# R7FA8D1BH register map
Vendor: Renesas; Series: RA8; File version: 1.2
CPU: CM85 r0p0, little endian, MPU, FPU, VTOR, 4 interrupt priority bits
Registers are 32-bit, read-write, reset 0x0 unless marked. A register's access mark holds for its fields unless they carry their own. Offsets are from the block's base; [hi:lo] are bit positions.

## ETHERC0 — Ethernet Controller Channel 0
Base 0x40354100
Same registers: ETHERC0_NS 0x50354100
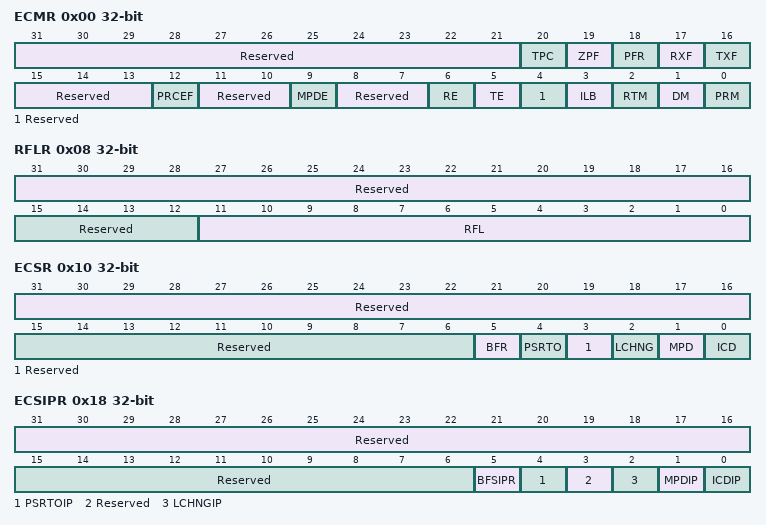
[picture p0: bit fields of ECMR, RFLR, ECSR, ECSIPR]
0x00 ECMR — ETHERC Mode Register
  [31:21] Reserved — These bits are read as 00000000000. The write value should be 00000000000.
  [20] TPC — PAUSE Frame Transmit
    0=PAUSE frame is transmitted even during a PAUSE period; 1=PAUSE frame is not transmitted during a PAUSE period
  [19] ZPF — 0 Time PAUSE Frame Enable
    0=PAUSE frame that contains the pause_time parameter of 0 is not used; 1=PAUSE frame that contains the pause_time parameter of 0 is used
  [18] PFR — PAUSE Frame Receive Mode
    0=PAUSE frame is not transferred to the EDMAC; 1=PAUSE frame is transferred to the EDMAC
  [17] RXF — Receive Flow Control Operating Mode
    0=PAUSE frame detection is disabled; 1=PAUSE frame detection is enabled
  [16] TXF — Transmit Flow Control Operating Mode
    0=Automatic PAUSE frame transmission is disabled.(PAUSE frame is not automatically transmitted.); 1=Automatic PAUSE frame transmission is enabled.(PAUSE frame is automatically transmitted as required.)
  [15:13] Reserved — These bits are read as 000. The write value should be 000.
  [12] PRCEF — CRC Error Frame Receive Mode
    0=EDMAC is notified of a CRC error; 1=EDMAC is not notified of a CRC error
  [11:10] Reserved — These bits are read as 00. The write value should be 00.
  [9] MPDE — Magic Packet Detection Enable
    0=Magic Packet detection is disabled; 1=Magic Packet detection is enabled
  [8:7] Reserved — These bits are read as 00. The write value should be 00.
  [6] RE — Reception Enable
    0=Receive function is disabled; 1=Receive function is enabled
  [5] TE — Transmission Enable
    0=Transmit function is disabled; 1=Transmit function is enabled
  [4] Reserved — This bit is read as 0. The write value should be 0.
  [3] ILB — Internal Loopback Mode
    0=Normal data transmission or reception is performed; 1=Data is looped back in the ETHERC when full-duplex mode is selected
  [2] RTM — Bit Rate
    0=10 Mbps; 1=100 Mbps
  [1] DM — Duplex Mode
    0=Half-duplex mode; 1=Full-duplex mode
  [0] PRM — Promiscuous Mode
    0=Promiscuous mode is disabled; 1=Promiscuous mode is enabled
0x08 RFLR — Receive Frame Maximum Length Register
  [31:16] Reserved — These bits are read as 0000000000000000. The write value should be 0000000000000000.
  [15:12] Reserved — These bits are read as 0000. The write value should be 0000.
  [11:0] RFL — Receive Frame Maximum LengthThe set value becomes the maximum frame length. The minimum value that can be set is 1,518 bytes, and the maximum value that can be set is 2,048 bytes. Values that are less than 1,518 bytes are regarded as 1,518 bytes, and values larger than 2,048 bytes are regarded as 2,048 bytes.
0x10 ECSR — ETHERC Status Register
  [31:16] Reserved — These bits are read as 0000000000000000. The write value should be 0000000000000000.
  [15:6] Reserved — These bits are read as 0000000000. The write value should be 0000000000.
  [5] BFR write-1-clears read-modifies — Continuous Broadcast Frame Reception Flag
    0=Continuous reception of broadcast frames has not been detected; 1=Continuous reception of broadcast frames has been detected
  [4] PSRTO write-1-clears read-modifies — PAUSE Frame Retransmit Over Flag
    0=PAUSE frame retransmit count has not reached the upper limit; 1=PAUSE frame retransmit count has reached the upper limit
  [3] Reserved — This bit is read as 0. The write value should be 0.
  [2] LCHNG write-1-clears read-modifies — LCHNG Link Signal Change Flag
    0=Change in the ETn_LINKSTA signal has not been detected; 1=Change in the ETn_LINKSTA signal has been detected (high to low, or low to high)
  [1] MPD write-1-clears read-modifies — Magic Packet Detect Flag
    0=Magic Packet has not been detected; 1=Magic Packet has been detected
  [0] ICD write-1-clears read-modifies — False Carrier Detect Flag
    0=PHY-LSI has not detected a false carrier on the line; 1=PHY-LSI has detected a false carrier on the line
0x18 ECSIPR — ETHERC Interrupt Enable Register
  [31:16] Reserved — These bits are read as 0000000000000000. The write value should be 0000000000000000.
  [15:6] Reserved — These bits are read as 0000000000. The write value should be 0000000000.
  [5] BFSIPR — Continuous Broadcast Frame Reception Interrupt Enable
    0=Notification of continuous broadcast frame reception interrupt is disabled; 1=Notification of continuous broadcast frame reception interrupt is enabled
  [4] PSRTOIP — PAUSE Frame Retransmit Over Interrupt Enable
    0=Notification of PAUSE frame retransmit over interrupt is disabled; 1=Notification of PAUSE frame retransmit over interrupt is enabled
  [3] Reserved — This bit is read as 0. The write value should be 0.
  [2] LCHNGIP — LINK Signal Change Interrupt Enable
    0=Notification of ETn_LINKSTA signal change interrupt is disabled; 1=Notification of ETn_LINKSTA signal change interrupt is enabled
  [1] MPDIP — Magic Packet Detect Interrupt Enable
    0=Notification of the Magic Packet detect interrupt is disabled; 1=Notification of the Magic Packet detect interrupt is enabled
  [0] ICDIP — False Carrier Detect Interrupt Enable
    0=Notification of the false carrier detect interrupt is disabled; 1=Notification of the false carrier detect interrupt is enabled
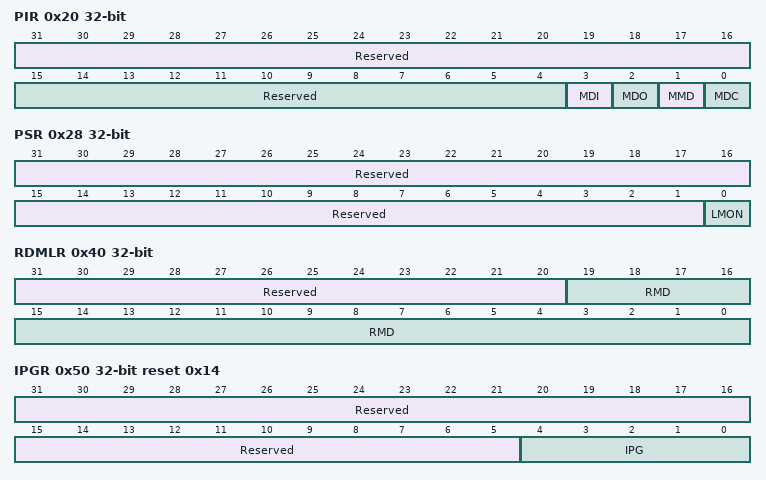
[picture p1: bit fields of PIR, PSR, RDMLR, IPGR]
0x20 PIR (reset mask 0xFFFFFFF7) — PHY Interface Register
  [31:16] Reserved — These bits are read as 0000000000000000. The write value should be 0000000000000000.
  [15:4] Reserved — These bits are read as 000000000000. The write value should be 000000000000.
  [3] MDI ro — MII/RMII Management Data-InThis bit indicates the level of the ETn_MDIO pin. The write value should be 0.
  [2] MDO — MII/RMII Management Data-OutThe MDO bit value is output from the ETn_MDIO pin when the MMD bit is 1 (write). The value is not output when the MMD bit is 0 (read).
  [1] MMD — MII/RMII Management Mode
    0=Read; 1=Write
  [0] MDC — MII/RMII Management Data ClockThe MDC bit value is output from the ETn_MDC pin to supply the management data clock to the MII or RMII.
0x28 PSR ro (reset mask 0xFFFFFFFE) — PHY Status Register
  [31:1] Reserved — These bits are read as 0000000000000000000000000000000.
  [0] LMON — ETn_LINKSTA Pin Status FlagThe link status can be read by connecting the link signal output from the PHY-LSI to the ETn_LINKSTA pin. For details on the polarity, refer to the specifications of the connected PHY-LSI.
0x40 RDMLR — Random Number Generation Counter Upper Limit Setting Register
  [31:20] Reserved — These bits are read as 000000000000. The write value should be 000000000000.
  [19:0] RMD — Random Number Generation Counter
    0=00000h (Normal operation); other=others (Setting prohibited)
0x50 IPGR reset 0x14 — IPG Register
  [31:5] Reserved — These bits are read as 000000000000000000000000000. The write value should be 000000000000000000000000000.
  [4:0] IPG — Interpacket Gap Range from 16bit time(0x00) to 140bit time(0x1F)
    20=14h (96 bit time (initial value)); other=others ((IPGx4+16) bit time)
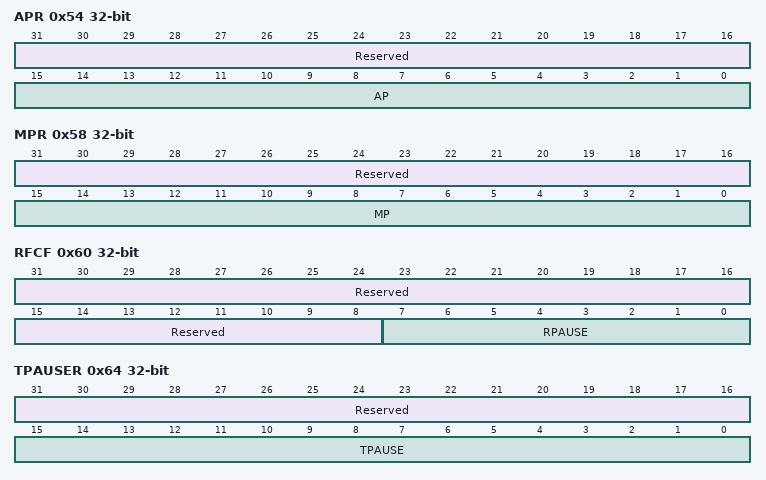
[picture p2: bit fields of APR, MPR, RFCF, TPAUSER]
0x54 APR — Automatic PAUSE Frame Register
  [31:16] Reserved — These bits are read as 0000000000000000. The write value should be 0000000000000000.
  [15:0] AP — Automatic PAUSE Time SettingThese bits set the value of the pause_time parameter for a PAUSE frame that is automatically transmitted. Transmission is not performed until the set value multiplied by 512 bit time has elapsed.
0x58 MPR (reset mask 0xFFFF0000) — Manual PAUSE Frame Register
  [31:16] Reserved — These bits are read as 0000000000000000. The write value should be 0000000000000000.
  [15:0] MP — Manual PAUSE Time SettingThese bits set the value of the pause_time parameter for a PAUSE frame that is manually transmitted. Transmission is not performed until the set value multiplied by 512 bit time has elapsed. The read value is undefined.
0x60 RFCF ro — Received PAUSE Frame Counter
  [31:8] Reserved — These bits are read as 000000000000000000000000.
  [7:0] RPAUSE — Received PAUSE Frame CountNumber of received PAUSE frames
0x64 TPAUSER — PAUSE Frame Retransmit Count Setting Register
  [31:16] Reserved — These bits are read as 0000000000000000. The write value should be 0000000000000000.
  [15:0] TPAUSE — Automatic PAUSE Frame Retransmit Setting
    0=Number of retransmissions is unlimited; other=others (Maximum number of retransmissions is (TPAUSE))
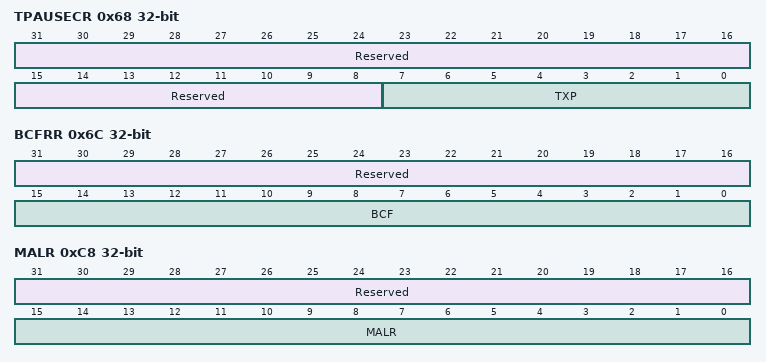
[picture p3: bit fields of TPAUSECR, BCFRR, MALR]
0x68 TPAUSECR ro — PAUSE Frame Retransmit Counter
  [31:8] Reserved — These bits are read as 000000000000000000000000.
  [7:0] TXP — PAUSE Frame Retransmit CountNumber of times a PAUSE frame was retransmitted
0x6C BCFRR — Broadcast Frame Receive Count Setting Register
  [31:16] Reserved — These bits are read as 0000000000000000. The write value should be 0000000000000000.
  [15:0] BCF — Broadcast Frame Continuous Receive Count Setting
    0=0000h (Number of receptions is unlimited.); other=others (Receive (BFC) frame.)
0xC0 MAHR — MAC Address Upper Bit Register
  [31:0] MAHR — MAC Address Upper Bit RegisterThe MAHR register sets the upper 32 bits (b47 to b16) of the 48-bit MAC address.
0xC8 MALR — MAC Address Lower Bit Register
  [31:16] Reserved — These bits are read as 0000000000000000. The write value should be 0000000000000000.
  [15:0] MALR — MAC Address Lower Bit RegisterThe MALR register sets the lower 16 bits of the 48-bit MAC address.
0xD0 TROCR — Transmit Retry Over Counter Register
  [31:0] TROCR write-clears — Transmit Retry Over Counter RegisterThe TROCR register is a counter indicating the number of frames that fail to be retransmitted.
0xD4 CDCR — Late Collision Detect Counter Register
  [31:0] CDCR write-clears — Late Collision Detect Counter RegisterThe CDCR register is a counter indicating the number of late collisions that have been detected after transmission starts.
0xD8 LCCR — Lost Carrier Counter Register
  [31:0] LCCR write-clears — Lost Carrier Counter RegisterThe LCCR register is a counter indicating the number of times a loss of carrier is detected during frame transmission.
0xDC CNDCR — Carrier Not Detect Counter Register
  [31:0] CNDCR write-clears — Carrier Not Detect Counter RegisterThe CNDCR register is a counter indicating the number of times a carrier is not detected during preamble transmission.
0xE4 CEFCR — CRC Error Frame Receive Counter Register
  [31:0] CEFCR write-clears — CRC Error Frame Receive Counter RegisterThe CEFCR register is a counter indicating the number of received frames where a CRC error has been detected.
0xE8 FRECR — Frame Receive Error Counter Register
  [31:0] FRECR write-clears — Frame Receive Error Counter RegisterThe FRECR register is a counter indicating the number of times a frame receive error has occurred.
0xEC TSFRCR — Too-Short Frame Receive Counter Register
  [31:0] TSFRCR write-clears — Too-Short Frame Receive Counter RegisterThe TSFRCR register is a counter indicating the number of times a short frame that is shorter than 64 bytes has been received.
0xF0 TLFRCR — Too-Long Frame Receive Counter Register
  [31:0] TLFRCR write-clears — Too-Long Frame Receive Counter RegisterThe TLFRCR register is a counter indicating the number of times a long frame that is longer than the RFLR register value has been received.
0xF4 RFCR — Received Alignment Error Frame Counter Register
  [31:0] RFCR write-clears — Received Alignment Error Frame Counter RegisterThe RFCR register is a counter indicating the number of times a frame has been received with the alignment error (frame is not an integral number of octets).
0xF8 MAFCR — Multicast Address Frame Receive Counter Register
  [31:0] MAFCR write-clears — Multicast Address Frame Receive Counter RegisterThe MAFCR register is a counter indicating the number of times a frame where the multicast address is set has been received.
